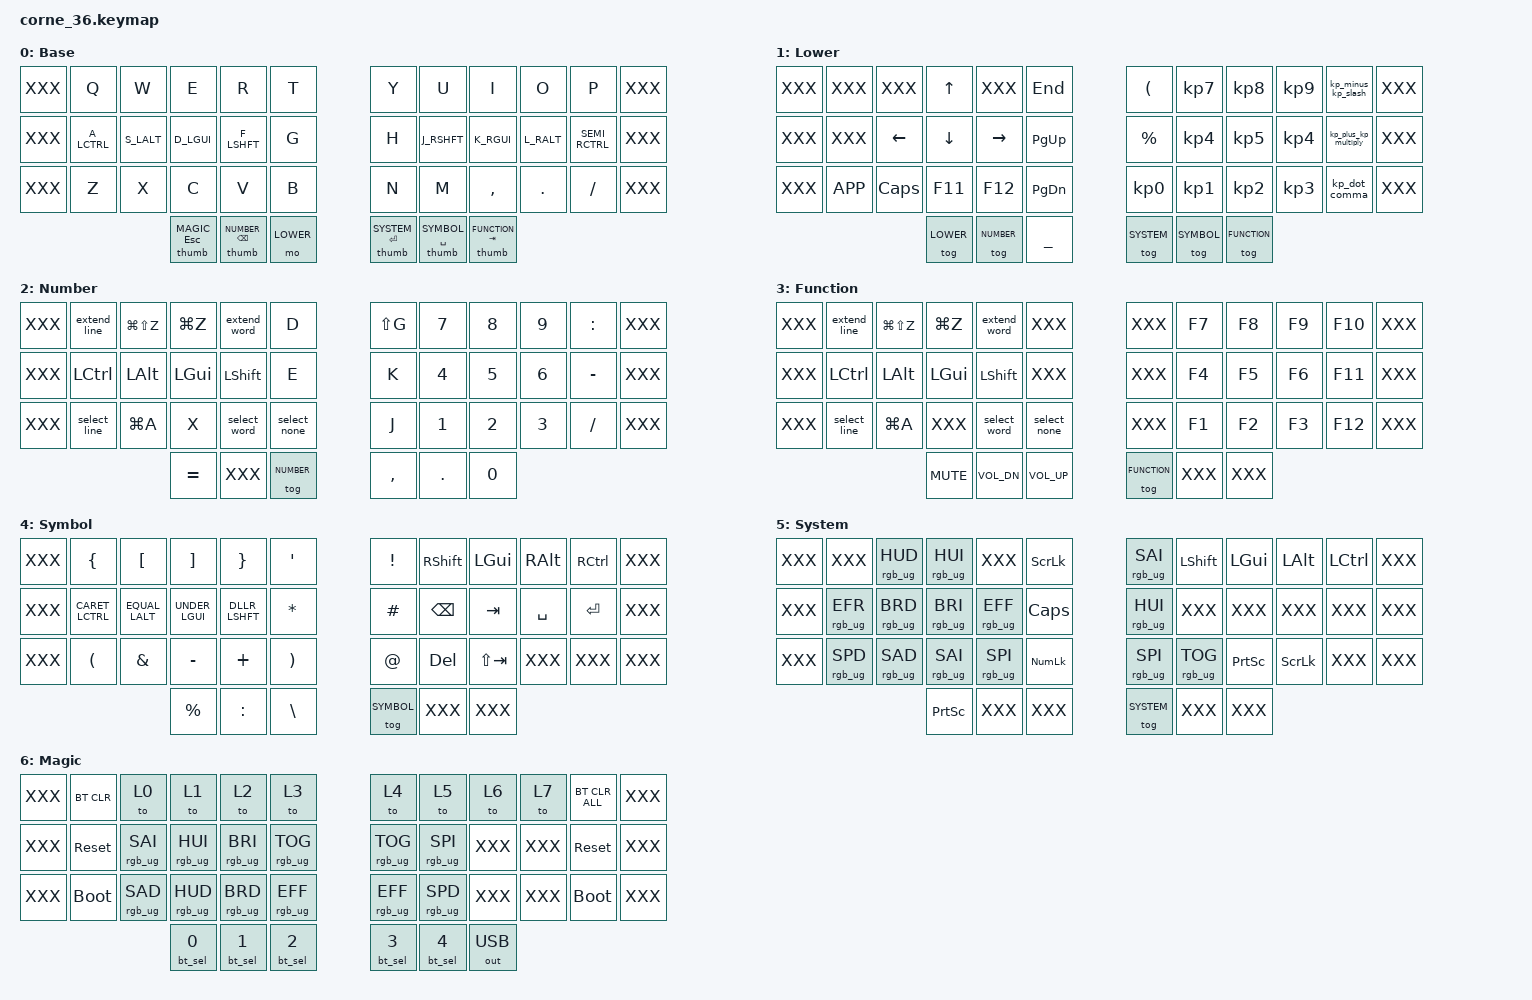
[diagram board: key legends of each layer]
#include <behaviors.dtsi>

#include <dt-bindings/zmk/keys.h>
#include <dt-bindings/zmk/ext_power.h>
#include <dt-bindings/zmk/bt.h>
#include <dt-bindings/zmk/rgb.h>
#include <dt-bindings/zmk/outputs.h>

#include "zmk-helpers/helper.h"
#include "zmk-helpers/key-labels/42.h"

#include "./mouse.dtsi"

#define LEFT_HAND_KEYS   LT4 LT3 LT2 LT1 LT0 \
                         LM4 LM3 LM2 LM1 LM0 \
                         LB4 LB3 LB2 LB1 LB0

#define RIGHT_HAND_KEYS  RT0 RT1 RT2 RT3 RT4 \
                         RM0 RM1 RM2 RM3 RM4 \
                         RB0 RB1 RB2 RB3 RB4

#define THUMB_KEYS       LH2 LH1 LH0     RH0 RH1 RH2

#include "general.h"
#include "homerow_mods.h"
#include "custom_behaviors.h"

#define BASE      0
#define LOWER     1
#define NUMBER    2
#define FUNCTION  3
#define SYMBOL    4
#define SYSTEM    5
#define MAGIC     6

ZMK_COMBO(magic_thumb_left, &magic MAGIC 0, LH2 LH0, BASE)
ZMK_COMBO(magic_thumb_right, &magic MAGIC 0, RH0 RH2, BASE)

ZMK_LAYER(Base,
// ╭───────────────┬───────────────┬───────────────┬───────────────┬───────────────╮   ╭───────────────┬───────────────┬───────────────┬───────────────┬───────────────╮
XXX  &kp Q           &kp W           &kp E           &kp R           &kp T               &kp Y           &kp U           &kp I           &kp O           &kp P          XXX
// ├───────────────┼───────────────┼───────────────┼───────────────┼───────────────┤   ├───────────────┼───────────────┼───────────────┼───────────────┼───────────────┤
XXX  A_LCTRL         S_LALT          D_LGUI          F_LSHFT         &kp G               &kp H           J_RSHFT         K_RGUI          L_RALT          SEMI_RCTRL     XXX
// ├───────────────┼───────────────┼───────────────┼───────────────┼───────────────┤   ├───────────────┼───────────────┼───────────────┼───────────────┼───────────────┤
XXX  &kp Z           &kp X           &kp C           &kp V           &kp B               &kp N           &kp M           &kp COMMA       &kp DOT         &kp FSLH       XXX
// ╰───────────────┴───────────────┴───────────────┴───────────────┴───────────────╯   ╰───────────────┴───────────────┴───────────────┴───────────────┴───────────────╯
//                     ╭───────────────────┬────────────────────┬───────────────╮         ╭───────────────────┬─────────────────────┬─────────────────────╮
                         &thumb MAGIC ESC    &thumb NUMBER BSPC   &mo LOWER                 &thumb SYSTEM RET   &thumb SYMBOL SPACE   &thumb FUNCTION TAB
//                     ╰───────────────────┴────────────────────┴───────────────╯         ╰───────────────────┴─────────────────────┴─────────────────────╯
)

ZMK_LAYER(Lower,
// ╭───────────────┬───────────────┬───────────────┬───────────────┬───────────────╮   ╭───────────────┬───────────────┬───────────────┬───────────────┬───────────────────────╮
XXX  XXX             XXX             &kp UP          XXX             &kp END             &kp LPAR        &kp KP_N7       &kp KP_N8       &kp KP_N9       &kp_minus_kp_slash     XXX
// ├───────────────┼───────────────┼───────────────┼───────────────┼───────────────┤   ├───────────────┼───────────────┼───────────────┼───────────────┼───────────────────────┤
XXX  XXX             &kp LEFT        &kp DOWN        &kp RIGHT       &kp PG_UP           &kp PRCNT       &kp KP_N4       &kp KP_N5       &kp KP_N4       &kp_plus_kp_multiply   XXX
// ├───────────────┼───────────────┼───────────────┼───────────────┼───────────────┤   ├───────────────┼───────────────┼───────────────┼───────────────┼───────────────────────┤
XXX  &kp K_APP       &kp CAPS        &kp F11         &kp F12         &kp PG_DN           &kp KP_N0       &kp KP_N1       &kp KP_N2       &kp KP_N3       &kp_dot_comma          XXX
// ╰───────────────┴───────────────┴───────────────┴───────────────┴───────────────╯   ╰───────────────┴───────────────┴───────────────┴───────────────┴───────────────────────╯
//                              ╭───────────────┬───────────────┬───────────────╮         ╭───────────────┬───────────────┬───────────────╮
                                  &tog LOWER      &tog NUMBER     ___                       &tog SYSTEM     &tog SYMBOL     &tog FUNCTION 
//                              ╰───────────────┴───────────────┴───────────────╯         ╰───────────────┴───────────────┴───────────────╯
)

ZMK_LAYER(Number,
// ╭───────────────┬───────────────┬───────────────┬───────────────┬───────────────╮   ╭───────────────┬───────────────┬───────────────┬───────────────┬───────────────╮
XXX  &extend_line    &kp LG(LS(Z))   &kp LG(Z)       &extend_word    &kp D               &kp LS(G)       &kp N7          &kp N8          &kp N9          &kp COLON      XXX
// ├───────────────┼───────────────┼───────────────┼───────────────┼───────────────┤   ├───────────────┼───────────────┼───────────────┼───────────────┼───────────────┤
XXX  &kp LCTRL       &kp LALT        &kp LGUI        &kp LSHFT       &kp E               &kp K           &kp N4          &kp N5          &kp N6          &kp MINUS      XXX
// ├───────────────┼───────────────┼───────────────┼───────────────┼───────────────┤   ├───────────────┼───────────────┼───────────────┼───────────────┼───────────────┤
XXX  &select_line    &kp LG(A)       &kp X           &select_word    &select_none        &kp J           &kp N1          &kp N2          &kp N3          &kp SLASH      XXX
// ╰───────────────┴───────────────┴───────────────┴───────────────┴───────────────╯   ╰───────────────┴───────────────┴───────────────┴───────────────┴───────────────╯
//                              ╭───────────────┬───────────────┬───────────────╮         ╭───────────────┬───────────────┬───────────────╮
                                  &kp EQUAL       XXX             &tog NUMBER               &kp COMMA       &kp DOT         &kp N0
//                              ╰───────────────┴───────────────┴───────────────╯         ╰───────────────┴───────────────┴───────────────╯
)

ZMK_LAYER(Function,
// ╭───────────────┬───────────────┬───────────────┬───────────────┬───────────────╮   ╭───────────────┬───────────────┬───────────────┬───────────────┬───────────────╮
XXX  &extend_line    &kp LG(LS(Z))   &kp LG(Z)       &extend_word    XXX                 XXX             &kp F7          &kp F8          &kp F9          &kp F10        XXX
// ├───────────────┼───────────────┼───────────────┼───────────────┼───────────────┤   ├───────────────┼───────────────┼───────────────┼───────────────┼───────────────┤
XXX  &kp LCTRL       &kp LALT        &kp LGUI        &kp LSHFT       XXX                 XXX             &kp F4          &kp F5          &kp F6          &kp F11        XXX
// ├───────────────┼───────────────┼───────────────┼───────────────┼───────────────┤   ├───────────────┼───────────────┼───────────────┼───────────────┼───────────────┤
XXX  &select_line    &kp LG(A)       XXX             &select_word    &select_none        XXX             &kp F1          &kp F2          &kp F3          &kp F12        XXX
// ╰───────────────┴───────────────┴───────────────┴───────────────┴───────────────╯   ╰───────────────┴───────────────┴───────────────┴───────────────┴───────────────╯
//                              ╭───────────────┬───────────────┬───────────────╮         ╭───────────────┬───────────────┬───────────────╮
                                  &kp C_MUTE      &kp C_VOL_DN    &kp C_VOL_UP              &tog FUNCTION   XXX             XXX
//                              ╰───────────────┴───────────────┴───────────────╯         ╰───────────────┴───────────────┴───────────────╯
)

ZMK_LAYER(Symbol,
// ╭───────────────┬───────────────┬───────────────┬───────────────┬───────────────╮   ╭───────────────┬───────────────┬───────────────┬───────────────┬───────────────╮
XXX  &kp LBRC        &kp LBKT        &kp RBKT        &kp RBRC        &kp SQT             &kp EXCL        &kp RSHFT       &kp LGUI        &kp RALT        &kp RCTRL      XXX
// ├───────────────┼───────────────┼───────────────┼───────────────┼───────────────┤   ├───────────────┼───────────────┼───────────────┼───────────────┼───────────────┤
XXX  CARET_LCTRL     EQUAL_LALT      UNDER_LGUI      DLLR_LSHFT      &kp STAR            &kp HASH        &kp BSPC        &kp TAB         &kp SPC         &kp ENTER      XXX
// ├───────────────┼───────────────┼───────────────┼───────────────┼───────────────┤   ├───────────────┼───────────────┼───────────────┼───────────────┼───────────────┤
XXX  &kp LPAR        &kp AMPS        &kp MINUS       &kp PLUS        &kp RPAR            &kp AT          &kp DEL         &kp LS(TAB)     XXX             XXX            XXX
// ╰───────────────┴───────────────┴───────────────┴───────────────┴───────────────╯   ╰───────────────┴───────────────┴───────────────┴───────────────┴───────────────╯
//                              ╭───────────────┬───────────────┬───────────────╮         ╭───────────────┬───────────────┬───────────────╮
                                  &kp PRCNT       &kp COLON       &kp BSLH                  &tog SYMBOL     XXX             XXX
//                              ╰───────────────┴───────────────┴───────────────╯         ╰───────────────┴───────────────┴───────────────╯
)

ZMK_LAYER(System,
// ╭─────────────────┬─────────────────┬─────────────────┬─────────────────┬───────────────╮   ╭─────────────────┬─────────────────┬───────────────┬───────────────┬──────────────────╮
XXX  XXX               &rgb_ug RGB_HUD   &rgb_ug RGB_HUI   XXX               &kp SLCK            &rgb_ug RGB_SAI   &kp LSHFT         &kp LGUI        &kp LALT        &kp LCTRL         XXX
// ├─────────────────┼─────────────────┼─────────────────┼─────────────────┼───────────────┤   ├─────────────────┼─────────────────┼───────────────┼───────────────┼──────────────────┤
XXX  &rgb_ug RGB_EFR   &rgb_ug RGB_BRD   &rgb_ug RGB_BRI   &rgb_ug RGB_EFF   &kp CAPS            &rgb_ug RGB_HUI   XXX               XXX             XXX             XXX               XXX
// ├─────────────────┼─────────────────┼─────────────────┼─────────────────┼───────────────┤   ├─────────────────┼─────────────────┼───────────────┼───────────────┼──────────────────┤
XXX  &rgb_ug RGB_SPD   &rgb_ug RGB_SAD   &rgb_ug RGB_SAI   &rgb_ug RGB_SPI   &kp KP_NUM          &rgb_ug RGB_SPI   &rgb_ug RGB_TOG   &kp PSCRN       &kp SLCK        XXX               XXX
// ╰─────────────────┴─────────────────┴─────────────────┴─────────────────┴───────────────╯   ╰─────────────────┴─────────────────┴───────────────┴───────────────┴──────────────────╯
//                                   ╭───────────────┬───────────────┬──────────────────╮         ╭───────────────┬───────────────┬───────────────╮
                                       &kp PSCRN       XXX             XXX                          &tog SYSTEM     XXX             XXX
//                                   ╰───────────────┴───────────────┴──────────────────╯         ╰───────────────┴───────────────┴───────────────╯
) 

ZMK_LAYER(Magic,
// ╭─────────────────┬─────────────────┬─────────────────┬─────────────────┬─────────────────╮   ╭─────────────────┬─────────────────┬───────────────┬───────────────┬───────────────╮
XXX  &bt BT_CLR        &to 0             &to 1             &to 2             &to 3                 &to 4             &to 5             &to 6           &to 7           &bt BT_CLR_ALL XXX
// ├─────────────────┼─────────────────┼─────────────────┼─────────────────┼─────────────────┤   ├─────────────────┼─────────────────┼───────────────┼───────────────┼───────────────┤
XXX  &sys_reset        &rgb_ug RGB_SAI   &rgb_ug RGB_HUI   &rgb_ug RGB_BRI   &rgb_ug RGB_TOG       &rgb_ug RGB_TOG   &rgb_ug RGB_SPI   XXX             XXX             &sys_reset     XXX
// ├─────────────────┼─────────────────┼─────────────────┼─────────────────┼─────────────────┤   ├─────────────────┼─────────────────┼───────────────┼───────────────┼───────────────┤
XXX  &bootloader       &rgb_ug RGB_SAD   &rgb_ug RGB_HUD   &rgb_ug RGB_BRD   &rgb_ug RGB_EFF       &rgb_ug RGB_EFF   &rgb_ug RGB_SPD   XXX             XXX             &bootloader    XXX
// ╰─────────────────┴─────────────────┴─────────────────┴─────────────────┴─────────────────╯   ╰─────────────────┴─────────────────┴───────────────┴───────────────┴───────────────╯
//                                              ╭───────────────┬───────────────┬───────────────╮         ╭───────────────┬───────────────┬───────────────╮
                                                  &bt_sel 0       &bt_sel 1       &bt_sel 2                 &bt_sel 3       &bt_sel 4       &out OUT_USB
//                                              ╰───────────────┴───────────────┴───────────────╯         ╰───────────────┴───────────────┴───────────────╯
)

////ZMK_LAYER(Template,
////// ╭───────────────┬───────────────┬───────────────┬───────────────┬───────────────╮   ╭───────────────┬───────────────┬───────────────┬───────────────┬───────────────╮
////XXX  XXX             XXX             XXX             XXX             XXX                 XXX             XXX             XXX             XXX             XXX            XXX
////// ├───────────────┼───────────────┼───────────────┼───────────────┼───────────────┤   ├───────────────┼───────────────┼───────────────┼───────────────┼───────────────┤
////XXX  XXX             XXX             XXX             XXX             XXX                 XXX             XXX             XXX             XXX             XXX            XXX
////// ├───────────────┼───────────────┼───────────────┼───────────────┼───────────────┤   ├───────────────┼───────────────┼───────────────┼───────────────┼───────────────┤
////XXX  XXX             XXX             XXX             XXX             XXX                 XXX             XXX             XXX             XXX             XXX            XXX
////// ╰───────────────┴───────────────┴───────────────┴───────────────┴───────────────╯   ╰───────────────┴───────────────┴───────────────┴───────────────┴───────────────╯
//////                              ╭───────────────┬───────────────┬───────────────╮         ╭───────────────┬───────────────┬───────────────╮
////                                  XXX             XXX             XXX                       XXX             XXX             XXX
//////                              ╰───────────────┴───────────────┴───────────────╯         ╰───────────────┴───────────────┴───────────────╯
////)
